# PIC32MX320F128L device description
Architecture: MIPS; Family: PIC32MX; Series: PIC32MX
Registers are 32-bit, read-write, no defined reset value unless marked. A register's access mark holds for its fields unless they carry their own. Offsets are from the block's base; [hi:lo] are bit positions; {n}, {i} and the like mark numbered series; 'fields as' and 'values as' point back to an identical list.

## RCON
Instances: RCON 0x1f80f600 in periph1
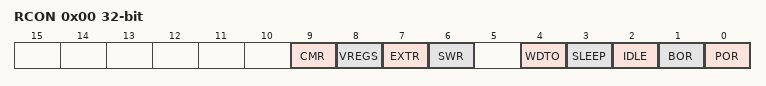
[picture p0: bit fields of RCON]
0x00 RCON — Reset Control Register
  [9] CMR — Configuration Mismatch Reset Flag bit
    1=Configuration mismatch Reset has occurred; 0=Configuration mismatch Reset has not occurred
  [8] VREGS — Voltage Regulator Standby Enable bit
    1=Regulator is enabled and is on during Sleep mode; 0=Regulator is set to standby tracking mode
  [7] EXTR — External Reset (MCLR) Pin Flag bit
    1=Master Clear (pin) Reset has occurred; 0=Master Clear (pin) Reset has not occurred
  [6] SWR — Software Reset Flag bit
    1=Software Reset was executed; 0=Software Reset as not executed
  [4] WDTO — Watchdog Timer Time-out Flag bit
    1=WDT Time-out has occurred; 0=WDT Time-out has not occurred
  [3] SLEEP — Wake From Sleep Flag bit
    1=Device was in Sleep mode; 0=Device was not in Sleep mode
  [2] IDLE — Wake From Idle Flag bit
    1=Device was in Idle mode; 0=Device was not in Idle mode
  [1] BOR — Brown-out Reset Flag bit
    1=Brown-out Reset has occurred; 0=Brown-out Reset has not occurred
  [0] POR — Power-on Reset Flag bit
    1=Power-on Reset has occurred; 0=Power-on Reset has not occurred
0x10 RSWRST — Software Reset Register
  [0] SWRST — Software Reset Trigger bit
    1=Enable Software Reset event; 0=No effect

## RTCC
Instances: RTCC 0x1f8001f4 in periph0
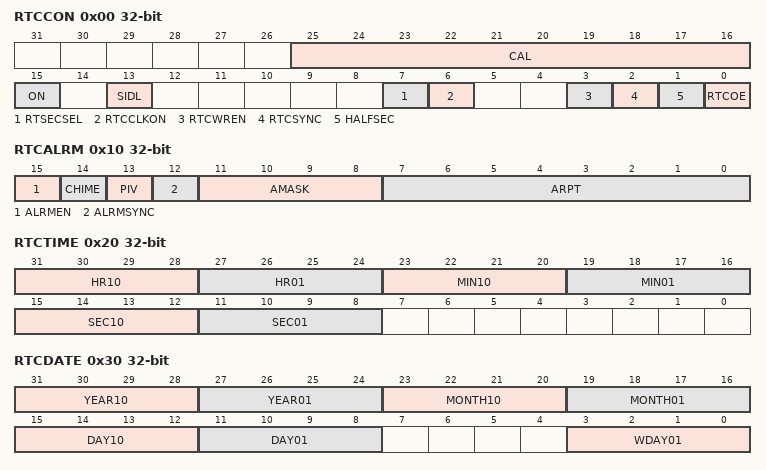
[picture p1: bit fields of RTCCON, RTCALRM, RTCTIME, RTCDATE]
0x00 RTCCON — RTC Control Register
  [25:16] CAL — RTC Drift Calibration bits
    0x1ff=Maximum positive adjustment, adds 511 RTC clock pulses every one minute; 1=Minimum positive adjustment, adds 1 RTC clock pulse every one minute; 0=No adjustment; 0x3ff=Minimum negative adjustment, subtracts 1 RTC clock pulse every one minute; 0x200=Maximum negative adjustment, subtracts 512 clock pulses every one minute
  [15] ON — RTCC On bit
    1=RTCC module is enabled; 0=RTCC module is disabled
  [13] SIDL — Stop in Idle Mode bit
    1=Disables the PBCLK to the RTCC when CPU enters in Idle mode; 0=Continue normal operation in Idle mode
  [7] RTSECSEL — RTCC Seconds Clock Output Select bit
    1=RTCC Seconds Clock is selected for the RTCC pin; 0=RTCC Alarm Pulse is selected for the RTCC pin
  [6] RTCCLKON — RTCC Clock Enable Status bit
    1=RTCC Clock is actively running; 0=RTCC Clock is not running
  [3] RTCWREN — RTC Value Registers Write Enable bit
    1=RTC Value registers can be written to by the user; 0=RTC Value registers are locked out from being written to by the user
  [2] RTCSYNC — RTCC Value Registers Read Synchronization bit
    1=RTC Value registers can change while reading due to a rollover ripple that results in an invalid data read; 0=RTC Value registers can be read without concern about a rollover ripple
  [1] HALFSEC — Half-Second Status bit
    1=Second half period of a second; 0=First half period of a second
  [0] RTCOE — RTCC Output Enable bit
    1=RTCC clock output is enabled clock presented onto an I/O; 0=RTCC clock output is disabled
0x10 RTCALRM — RTC ALARM Control Register
  [15] ALRMEN — Alarm Enable bit
    1=Alarm is enabled; 0=Alarm is disabled
  [14] CHIME — Chime Enable bit
    1=Chime is enabled ARPT(7:0) is allowed to rollover from 0x00 to 0xFF; 0=Chime is disabled ARPT(7:0) stops once it reaches 0x00
  [13] PIV — Alarm Pulse Initial Value bit
    1=(When ALRMEN = 0) Alarm pulse high / (When ALRMEN = 1) PIV is read-only and returns state of the alarm pulse; 0=(When ALRMEN = 0) Alarm pulse low / (When ALRMEN = 1) PIV is read-only and returns state of the alarm pulse
  [12] ALRMSYNC — Alarm Sync bit
    1=ARPT(7:0) and ALRMEN may change as a result of a half second rollover during a read; 0=ARPT(7:0) and ALRMEN can be read without concerns of rollover because the prescaler is more than 32 RTC clocks away from a half-second rollover
  [11:8] AMASK — Alarm Mask Configuration bits
    0=Every half-second; 1=Every second; 2=Every 10 seconds; 3=Every minute; 4=Every 10 minutes; 5=Every hour; 6=Once a day; 7=Once a week; 8=Once a month; 9=Once a year (except when configured for February 29; {v}=Reserved; do not use (v=10..15)
  [7:0] ARPT — Alarm Repeat Counter Value bits
    {v}=Alarm will trigger {v+1} times (v=0..255)
0x20 RTCTIME — RTC Time Value Register
  [31:28] HR10, [27:24] HR01, [23:20] MIN10, [19:16] MIN01, [15:12] SEC10, [11:8] SEC01
0x30 RTCDATE — RTC Date Value Register
  [31:28] YEAR10, [27:24] YEAR01, [23:20] MONTH10, [19:16] MONTH01, [15:12] DAY10, [11:8] DAY01, [3:0] WDAY01
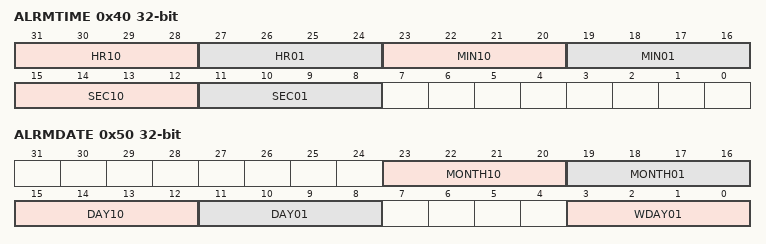
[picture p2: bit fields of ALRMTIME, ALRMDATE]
0x40 ALRMTIME — Alarm Time Value Register
  fields as RTCTIME
0x50 ALRMDATE — Alarm Date Value Register
  [23:20] MONTH10, [19:16] MONTH01, [15:12] DAY10, [11:8] DAY01, [3:0] WDAY01

## Notices in the file
Copyright (c) 2019 Microchip Technology Inc.
SPDX-License-Identifier: Apache-2.0
Licensed under the Apache License, Version 2.0 (the "License");
you may not use this file except in compliance with the License.
You may obtain a copy of the License at
http://www.apache.org/licenses/LICENSE-2.0
Unless required by applicable law or agreed to in writing, software
distributed under the License is distributed on an "AS IS" BASIS,
WITHOUT WARRANTIES OR CONDITIONS OF ANY KIND, either express or implied.
See the License for the specific language governing permissions and
limitations under the License.
